# daric register map
Vendor: cramium
Registers are 32-bit, read-write, reset 0x0 unless marked. A register's access mark holds for its fields unless they carry their own. Offsets are from the block's base; [hi:lo] are bit positions; {n}, {i} and the like mark numbered series.

## DKPC
Base 0x40064000
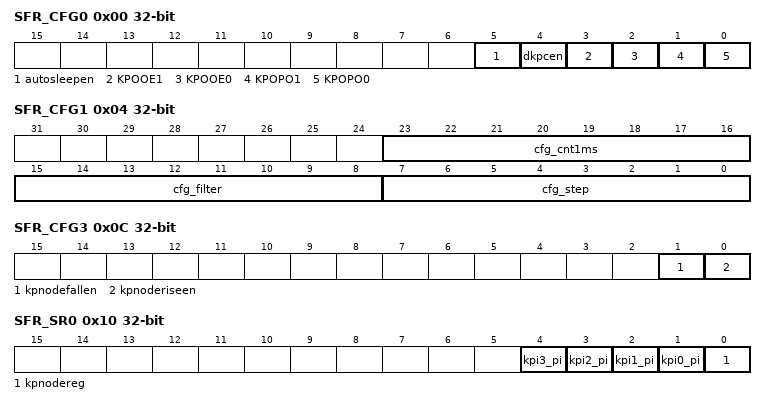
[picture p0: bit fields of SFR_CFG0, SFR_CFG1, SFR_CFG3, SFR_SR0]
0x00 SFR_CFG0 — See file:///F:/code/cram-nto/modules/ao/rtl/dkpc.sv
  [5] autosleepen — autosleepen read/write control register
  [4] dkpcen — dkpcen read/write control register
  [3] KPOOE1 — KPOOE1 read/write control register
  [2] KPOOE0 — KPOOE0 read/write control register
  [1] KPOPO1 — KPOPO1 read/write control register
  [0] KPOPO0 — KPOPO0 read/write control register
0x04 SFR_CFG1 — See file:///F:/code/cram-nto/modules/ao/rtl/dkpc.sv
  [23:16] cfg_cnt1ms — cfg_cnt1ms read/write control register
  [15:8] cfg_filter — cfg_filter read/write control register
  [7:0] cfg_step — cfg_step read/write control register
0x08 SFR_CFG2 — See file:///F:/code/cram-nto/modules/ao/rtl/dkpc.sv
  [31:0] cfg_cnt — cfg_cnt read/write control register
0x0C SFR_CFG3 — See file:///F:/code/cram-nto/modules/ao/rtl/dkpc.sv
  [1] kpnodefallen — kpnodefallen read/write control register
  [0] kpnoderiseen — kpnoderiseen read/write control register
0x10 SFR_SR0 — See file:///F:/code/cram-nto/modules/ao/rtl/dkpc.sv
  [n+1] kpi{n}_pi (n=0..3) — kpi[{n}].pi read only status register
  [0] kpnodereg — kpnodereg read only status register
0x14 SFR_SR1 — See file:///F:/code/cram-nto/modules/ao/rtl/dkpc.sv
  [0] sfr_sr1 — sfr_sr1 read only status register
0x30 SFR_CFG4 — See file:///F:/code/cram-nto/modules/ao/rtl/dkpc.sv
  [15:0] sfr_cfg4 — sfr_cfg4 read/write control register

## UDMA_CTRL
Base 0x50100000
0x00 REG_CG — See file:///F:/code/cram-nto/ips/udma/udma_core/rtl/common/udma_ctrl.sv
  [5:0] r_cg
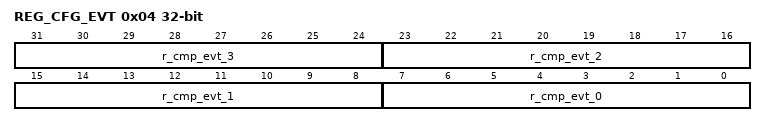
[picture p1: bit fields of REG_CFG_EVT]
0x04 REG_CFG_EVT — See file:///F:/code/cram-nto/ips/udma/udma_core/rtl/common/udma_ctrl.sv
  [8n+7:8n] r_cmp_evt_{n} (n=0..3)
0x08 REG_RST — See file:///F:/code/cram-nto/ips/udma/udma_core/rtl/common/udma_ctrl.sv
  [5:0] r_rst

## UDMA_UART_0
Base 0x50101000
Same registers: UDMA_UART_1 0x50102000, UDMA_UART_2 0x50103000, UDMA_UART_3 0x50104000
0x00 REG_RX_SADDR — See file:///F:/code/cram-nto/ips/udma/udma_uart/rtl/udma_uart_reg_if.sv
  [11:0] r_rx_startaddr
0x04 REG_RX_SIZE — See file:///F:/code/cram-nto/ips/udma/udma_uart/rtl/udma_uart_reg_if.sv
  [15:0] r_rx_size
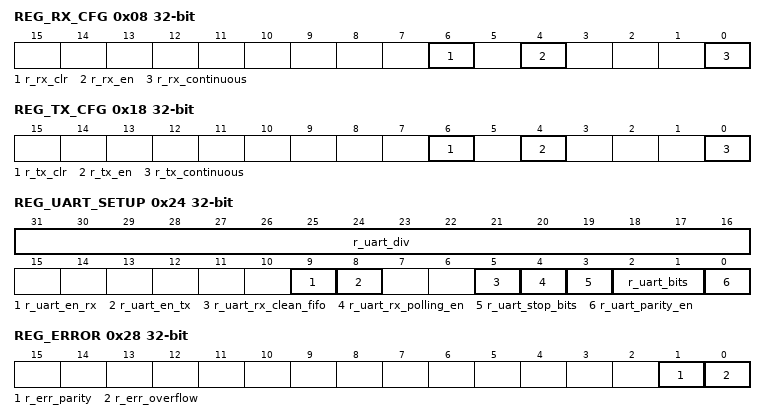
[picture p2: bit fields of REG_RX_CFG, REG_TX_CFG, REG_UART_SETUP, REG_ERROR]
0x08 REG_RX_CFG — See file:///F:/code/cram-nto/ips/udma/udma_uart/rtl/udma_uart_reg_if.sv
  [6] r_rx_clr, [4] r_rx_en, [0] r_rx_continuous
0x10 REG_TX_SADDR — See file:///F:/code/cram-nto/ips/udma/udma_uart/rtl/udma_uart_reg_if.sv
  [11:0] r_tx_startaddr
0x14 REG_TX_SIZE — See file:///F:/code/cram-nto/ips/udma/udma_uart/rtl/udma_uart_reg_if.sv
  [15:0] r_tx_size
0x18 REG_TX_CFG — See file:///F:/code/cram-nto/ips/udma/udma_uart/rtl/udma_uart_reg_if.sv
  [6] r_tx_clr, [4] r_tx_en, [0] r_tx_continuous
0x20 REG_STATUS — See file:///F:/code/cram-nto/ips/udma/udma_uart/rtl/udma_uart_reg_if.sv
  [0] status_i
0x24 REG_UART_SETUP — See file:///F:/code/cram-nto/ips/udma/udma_uart/rtl/udma_uart_reg_if.sv
  [31:16] r_uart_div, [9] r_uart_en_rx, [8] r_uart_en_tx, [5] r_uart_rx_clean_fifo, [4] r_uart_rx_polling_en, [3] r_uart_stop_bits, [2:1] r_uart_bits, [0] r_uart_parity_en
0x28 REG_ERROR — See file:///F:/code/cram-nto/ips/udma/udma_uart/rtl/udma_uart_reg_if.sv
  [1] r_err_parity, [0] r_err_overflow
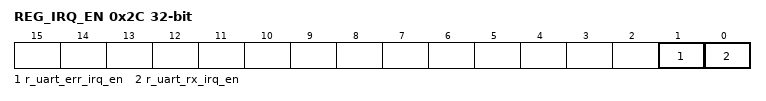
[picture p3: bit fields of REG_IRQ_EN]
0x2C REG_IRQ_EN — See file:///F:/code/cram-nto/ips/udma/udma_uart/rtl/udma_uart_reg_if.sv
  [1] r_uart_err_irq_en, [0] r_uart_rx_irq_en
0x30 REG_VALID — See file:///F:/code/cram-nto/ips/udma/udma_uart/rtl/udma_uart_reg_if.sv
  [0] r_uart_rx_data_valid
0x34 REG_DATA — See file:///F:/code/cram-nto/ips/udma/udma_uart/rtl/udma_uart_reg_if.sv
  [7:0] r_uart_rx_data

## UDMA_SPIM_0
Base 0x50105000
Same registers: UDMA_SPIM_1 0x50106000, UDMA_SPIM_2 0x50107000, UDMA_SPIM_3 0x50108000
0x00 REG_RX_SADDR — See file:///F:/code/cram-nto/ips/udma/udma_qspi/rtl/udma_spim_reg_if.sv
  [11:0] r_rx_startaddr
0x04 REG_RX_SIZE — See file:///F:/code/cram-nto/ips/udma/udma_qspi/rtl/udma_spim_reg_if.sv
  [15:0] r_rx_size
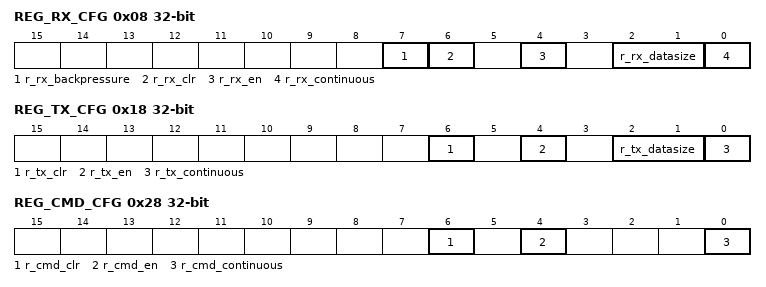
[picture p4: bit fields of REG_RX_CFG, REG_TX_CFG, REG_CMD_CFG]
0x08 REG_RX_CFG — See file:///F:/code/cram-nto/ips/udma/udma_qspi/rtl/udma_spim_reg_if.sv
  [7] r_rx_backpressure, [6] r_rx_clr, [4] r_rx_en, [2:1] r_rx_datasize, [0] r_rx_continuous
0x10 REG_TX_SADDR — See file:///F:/code/cram-nto/ips/udma/udma_qspi/rtl/udma_spim_reg_if.sv
  [11:0] r_tx_startaddr
0x14 REG_TX_SIZE — See file:///F:/code/cram-nto/ips/udma/udma_qspi/rtl/udma_spim_reg_if.sv
  [15:0] r_tx_size
0x18 REG_TX_CFG — See file:///F:/code/cram-nto/ips/udma/udma_qspi/rtl/udma_spim_reg_if.sv
  [6] r_tx_clr, [4] r_tx_en, [2:1] r_tx_datasize, [0] r_tx_continuous
0x20 REG_CMD_SADDR — See file:///F:/code/cram-nto/ips/udma/udma_qspi/rtl/udma_spim_reg_if.sv
  [11:0] r_cmd_startaddr
0x24 REG_CMD_SIZE — See file:///F:/code/cram-nto/ips/udma/udma_qspi/rtl/udma_spim_reg_if.sv
  [15:0] r_cmd_size
0x28 REG_CMD_CFG — See file:///F:/code/cram-nto/ips/udma/udma_qspi/rtl/udma_spim_reg_if.sv
  [6] r_cmd_clr, [4] r_cmd_en, [0] r_cmd_continuous
0x30 REG_STATUS — See file:///F:/code/cram-nto/ips/udma/udma_qspi/rtl/udma_spim_reg_if.sv
  [0] status_i
